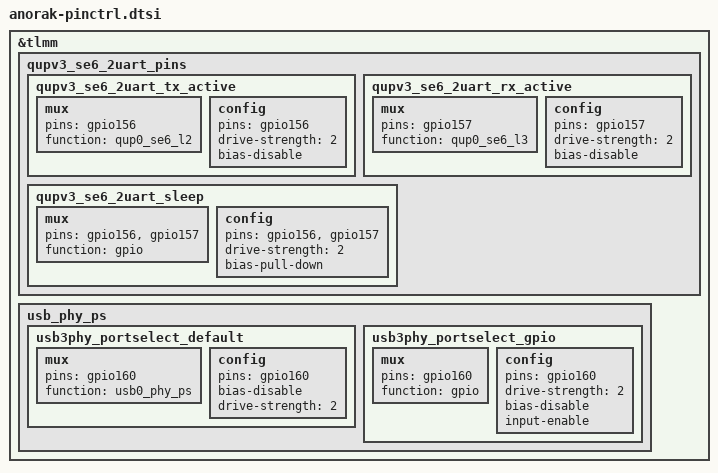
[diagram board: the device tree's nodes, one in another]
&tlmm {

	qupv3_se6_2uart_pins: qupv3_se6_2uart_pins {
		qupv3_se6_2uart_tx_active: qupv3_se6_2uart_tx_active {
			mux {
				pins = "gpio156";
				function = "qup0_se6_l2";
			};

			config {
				pins = "gpio156";
				drive-strength = <2>;
				bias-disable;
			};
		};

		qupv3_se6_2uart_rx_active: qupv3_se6_2uart_rx_active {
			mux {
				pins = "gpio157";
				function = "qup0_se6_l3";
			};

			config {
				pins = "gpio157";
				drive-strength = <2>;
				bias-disable;
			};
		};

		qupv3_se6_2uart_sleep: qupv3_se6_2uart_sleep {
			mux {
				pins = "gpio156", "gpio157";
				function = "gpio";
			};

			config {
				pins = "gpio156", "gpio157";
				drive-strength = <2>;
				bias-pull-down;
			};
		};
	};

	usb_phy_ps: usb_phy_ps {
		usb3phy_portselect_default: usb3phy_portselect_default {
			mux {
				pins = "gpio160";
				function = "usb0_phy_ps";
			};

			config {
				pins = "gpio160";
				bias-disable;
				drive-strength = <2>;
			};
		};

		usb3phy_portselect_gpio: usb3phy_portselect_gpio {
			mux {
				pins = "gpio160";
				function = "gpio";
			};

			config {
				pins = "gpio160";
				drive-strength = <2>;
				bias-disable;
				input-enable;
			};
		};
	};
};
